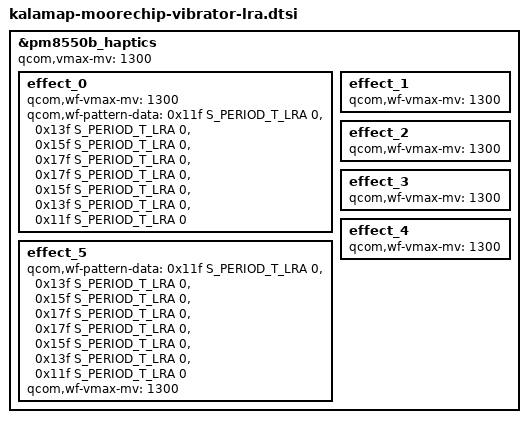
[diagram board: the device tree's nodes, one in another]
&pm8550b_haptics {
	status = "okay"; 
	qcom,vmax-mv = <1300>;

	effect_0 {
		/* CLICK */
		qcom,wf-vmax-mv = <1300>;
		qcom,wf-pattern-data =  <0x11f  S_PERIOD_T_LRA  0>,
					<0x13f  S_PERIOD_T_LRA  0>,
					<0x15f  S_PERIOD_T_LRA  0>,
					<0x17f  S_PERIOD_T_LRA  0>,
					<0x17f  S_PERIOD_T_LRA  0>,
					<0x15f  S_PERIOD_T_LRA  0>,
					<0x13f  S_PERIOD_T_LRA  0>,
					<0x11f  S_PERIOD_T_LRA  0>;
		/delete-property/ qcom,wf-pattern-preload;
	};

	effect_1 {
		/* DOUBLE_CLICK */
		qcom,wf-vmax-mv = <1300>;
	};

	effect_2 {
		/* TICK */
		qcom,wf-vmax-mv = <1300>;
	};

	effect_3 {
		/* THUD */
		qcom,wf-vmax-mv = <1300>;
	};

	effect_4 {
		/* POP */
		qcom,wf-vmax-mv = <1300>;
	};

	effect_5 {
		/* HEAVY CLICK */
		qcom,wf-pattern-data =  <0x11f  S_PERIOD_T_LRA  0>,
					<0x13f  S_PERIOD_T_LRA  0>,
					<0x15f  S_PERIOD_T_LRA  0>,
					<0x17f  S_PERIOD_T_LRA  0>,
					<0x17f  S_PERIOD_T_LRA  0>,
					<0x15f  S_PERIOD_T_LRA  0>,
					<0x13f  S_PERIOD_T_LRA  0>,
					<0x11f  S_PERIOD_T_LRA  0>;
		qcom,wf-vmax-mv = <1300>;
	};
};
